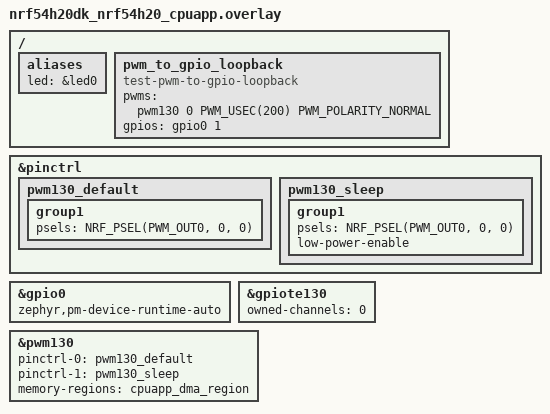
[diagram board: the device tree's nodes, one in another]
/*
 * Copyright (c) 2024 Nordic Semiconductor ASA
 *
 * SPDX-License-Identifier: LicenseRef-Nordic-5-Clause
 */

#include <zephyr/dt-bindings/pwm/pwm.h>
#include <zephyr/dt-bindings/gpio/nordic-nrf-gpio.h>

/* Test requires wire connection between:
 *  - PWM130 OUT[0] at P0.00
 *  - GPIO input at P0.01
 */

/ {
	aliases {
		led = &led0;
		/delete-property/ led1;
	};

	pwm_to_gpio_loopback: pwm_to_gpio_loopback {
		compatible = "test-pwm-to-gpio-loopback";
		pwms = <&pwm130 0 PWM_USEC(200) PWM_POLARITY_NORMAL>;
		gpios = <&gpio0 1 GPIO_ACTIVE_HIGH>;
	};
};

/delete-node/ &led1;

&pinctrl {
	/omit-if-no-ref/ pwm130_default: pwm130_default {
		group1 {
			psels = <NRF_PSEL(PWM_OUT0, 0, 0)>;
		};
	};

	/omit-if-no-ref/ pwm130_sleep: pwm130_sleep {
		group1 {
			psels = <NRF_PSEL(PWM_OUT0, 0, 0)>;
			low-power-enable;
		};
	};
};

&gpio0 {
	status = "okay";
	zephyr,pm-device-runtime-auto;
};

&gpiote130 {
	status = "okay";
	owned-channels = <0>;
};

&pwm130 {
	status = "okay";
	pinctrl-0 = <&pwm130_default>;
	pinctrl-1 = <&pwm130_sleep>;
	pinctrl-names = "default", "sleep";
	memory-regions = <&cpuapp_dma_region>;
};
